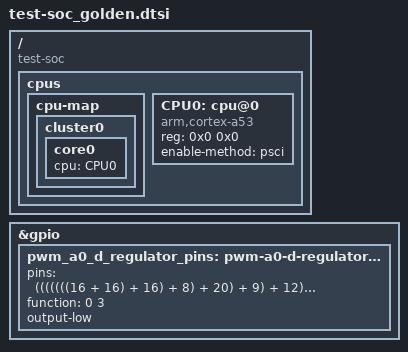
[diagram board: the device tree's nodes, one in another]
/dts-v1/;
/include/ "test-soc-common.dtsi"

/ {
 compatible = "test-soc";
 #address-cells = <2>;
 #size-cells = <2>;
 cpus:cpus {
  #address-cells = <2>;
  #size-cells = <0>;
  cpu-map {
   cluster0:cluster0 {
    core0 {
     cpu = <&CPU0>;
    };
   };
  };
  CPU0:cpu@0 {
   device_type = "cpu";
   compatible = "arm,cortex-a53","arm,armv8";
   reg = <0x0 0x0>;
   enable-method = "psci";
  };
 };
};
&gpio {
 pwm_a0_d_regulator_pins: pwm-a0-d-regulator-pins {
  pins = <(((((((16 + 16) + 16) + 8) + 20) + 9) + 12) + 1)>;
  function = <0 3>;
  output-low;
 };
};
